# gpio_intf_wrap: IP-XACT component
VLNV tenstorrent.com:ocah:gpio_intf_wrap:1.0

## Address spaces and blocks
gpio_intf_wrap_mmap.gpio_intf_wrap: base 'h0, range 'h430, width 32

## Registers
Registers are 32-bit, read-write, reset 0x0 unless marked. A register's access mark holds for its fields unless they carry their own. Offsets are from the block's base; lines under a group give offsets from that group; [hi:lo] are bit positions; {n}, {i} and the like mark numbered series; 'fields as' and 'values as' point back to an identical list; <NAME> marks a mode.

## gpio_intf_wrap_mmap.gpio_intf_wrap — Wrapper address map instantiating one GPIO interface register block per pad.
Base 0x00000000
{0x0+0x10*i} gpio_intf[{i}] (i=0..66) group — GPIO interface configuration: pad/core routing, receive and transmit enables, and interrupt control.
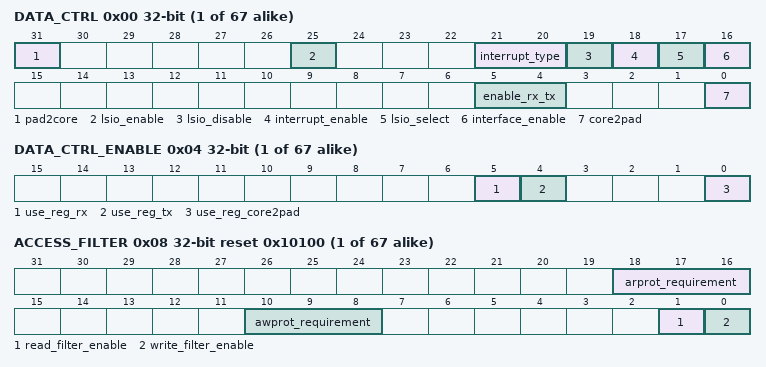
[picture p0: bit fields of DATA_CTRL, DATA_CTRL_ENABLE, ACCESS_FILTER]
  0x00 DATA_CTRL access per field
    [31] pad2core ro — PAD2SOC Value
    [25] lsio_enable ro — LSIO hardware request status. Set while lsio_interface_select_i is asserted and lsio_disable is clear. Because the hardware LSIO request outranks interface_enable, a set value also means the LSIO plane is driving this pad's data and direction. This field does not reflect a software-forced selection via lsio_select, which ranks below the register interface - it reads 0 in that case even when LSIO drives the pad.
    [21:20] interrupt_type rw — Interrupt type - 0: active-high level, 1: active-low level, 2: rising edge, 3: falling edge
    [19] lsio_disable rw — When set, LSIO accesses will be blocked from the GPIO interface
    [18] interrupt_enable rw
    [17] lsio_select rw — Force the LSIO interface to be used from software, when no hardware LSIO request is present on this pad. interface_enable has higher priority over this bit. This ranking applies to this software force bit only: the hardware lsio_interface_select_i input outranks interface_enable. Use lsio_disable to gate both.
    [16] interface_enable rw — Register Interface Enable. Setting this chooses register values to drive the PAD. This includes core2pad, enable_rx_tx, and pad2core
    [5:4] enable_rx_tx rw — Direction control. 2'b00: Neither RX nor TX enabled. 2'b01: TX enabled. 2'b10: RX enabled. 2'b11: Both enabled
    [0] core2pad rw — Register-driven data to send to the pad.
  0x04 DATA_CTRL_ENABLE
    [5] use_reg_rx — Per-field register override. When set, the RX direction (input enable) is taken from enable_rx_tx[1]. OR'd with interface_enable.
    [4] use_reg_tx — Per-field register override. When set, the TX direction (output enable) is taken from enable_rx_tx[0]. OR'd with interface_enable.
    [0] use_reg_core2pad — Per-field register override. When set, core2pad is register-driven. OR'd with interface_enable.
  0x08 ACCESS_FILTER reset 0x10100 — GPIO Access Filter Register. WARNING: please read back this register to ensure the filter was written correctly. If you do not do so the filter may not update before your next transaction, causing unexpected behavior.
    [18:16] arprot_requirement — When read_filter_enable is set, only allow read accesses with this prot value WARNING: please read back this register to ensure the filter was written correctly. If you do not do so the filter may not update before your next transaction, causing unexpected behavior.
    [10:8] awprot_requirement — When write_filter_enable is set, only allow write accesses with this prot value WARNING: please read back this register to ensure the filter was written correctly. If you do not do so the filter may not update before your next transaction, causing unexpected behavior.
    [1] read_filter_enable — Read Filter Enable. When set, reads require an exact match between AXI ARPROT and arprot_requirement. When clear, reads are unfiltered. PROT does not identify the initiator. WARNING: please read back this register to ensure the filter was written correctly. If you do not do so the filter may not update before your next transaction, causing unexpected behavior.
    [0] write_filter_enable — Write Filter Enable. When set, writes require an exact match between AXI AWPROT and awprot_requirement. When clear, writes are unfiltered. PROT does not identify the initiator. WARNING: please read back this register to ensure the filter was written correctly. If you do not do so the filter may not update before your next transaction, causing unexpected behavior.

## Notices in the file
SPDX-License-Identifier: Apache-2.0
SPDX-FileCopyrightText: 2026 Tenstorrent USA, Inc.
